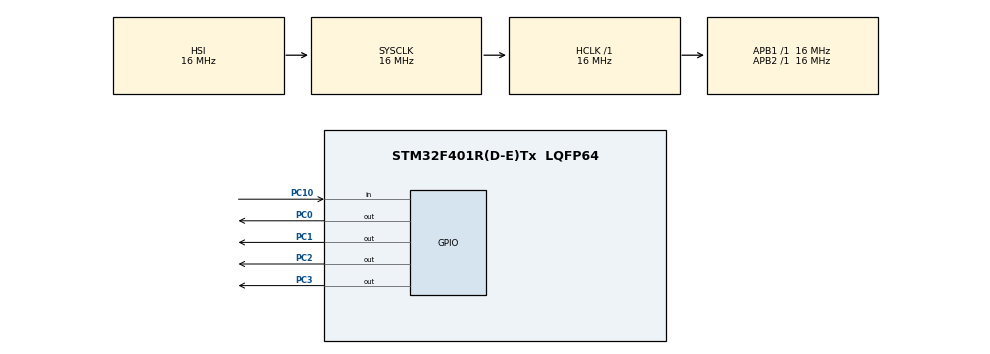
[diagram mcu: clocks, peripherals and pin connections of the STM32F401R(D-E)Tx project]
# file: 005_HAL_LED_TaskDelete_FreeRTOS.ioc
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FREERTOS.Tasks01=Task1,2,128,Task1Handler,Default,NULL,Dynamic,NULL,NULL;Task2,0,128,Task2Handler,Default,NULL,Dynamic,NULL,NULL
Mcu.Family=STM32F4
Mcu.Name=STM32F401R(D-E)Tx
Mcu.Package=LQFP64
NVIC.PriorityGroup=NVIC_PRIORITYGROUP_4
PC0.GPIO_Speed=GPIO_SPEED_FREQ_VERY_HIGH
PC0.Signal=GPIO_Output
PC1.GPIO_Speed=GPIO_SPEED_FREQ_VERY_HIGH
PC1.Signal=GPIO_Output
PC10.GPIO_PuPd=GPIO_PULLDOWN
PC10.Signal=GPIO_Input
PC2.GPIO_Speed=GPIO_SPEED_FREQ_VERY_HIGH
PC2.Signal=GPIO_Output
PC3.GPIO_Speed=GPIO_SPEED_FREQ_VERY_HIGH
PC3.Signal=GPIO_Output
ProjectManager.HeapSize=0x200
ProjectManager.StackSize=0x400
ProjectManager.TargetToolchain=STM32CubeIDE
RCC.AHBFreq_Value=16000000
RCC.APB1Freq_Value=16000000
RCC.APB2Freq_Value=16000000
RCC.CortexFreq_Value=16000000
RCC.HSE_VALUE=25000000
RCC.HSI_VALUE=16000000
RCC.LSE_VALUE=32768
RCC.SYSCLKFreq_VALUE=16000000
RCC.VCOOutputFreq_Value=192000000
VP_FREERTOS_VS_CMSIS_V1.Mode=CMSIS_V1
board=custom

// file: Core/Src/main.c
/* USER CODE BEGIN Header */
/**
  ******************************************************************************
  * @file           : main.c
  * @brief          : Main program body
  ******************************************************************************
  * @attention
  *
  * Copyright (c) 2023 STMicroelectronics.
  * All rights reserved.
  *
  * This software is licensed under terms that can be found in the LICENSE file
  * in the root directory of this software component.
  * If no LICENSE file comes with this software, it is provided AS-IS.
  *
  ******************************************************************************
  */
/* USER CODE END Header */
#include "main.h"
#include "cmsis_os.h"

osThreadId Task1Handle;
osThreadId Task2Handle;

void SystemClock_Config(void);
static void MX_GPIO_Init(void);
void Task1Handler(void const * argument);
void Task2Handler(void const * argument);

int main(void)
{

  /* MCU Configuration--------------------------------------------------------*/

  /* Reset of all peripherals, Initializes the Flash interface and the Systick. */
  HAL_Init();

  /* Configure the system clock */
  SystemClock_Config();

  /* Initialize all configured peripherals */
  MX_GPIO_Init();

  /* Create the thread(s) */
  /* definition and creation of Task1 */
  osThreadDef(Task1, Task1Handler, osPriorityHigh, 0, 128);
  Task1Handle = osThreadCreate(osThread(Task1), NULL);

  /* definition and creation of Task2 */
  osThreadDef(Task2, Task2Handler, osPriorityNormal, 0, 128);
  Task2Handle = osThreadCreate(osThread(Task2), NULL);

  /* Start scheduler */
  osKernelStart();
  /* We should never get here as control is now taken by the scheduler */
  /* Infinite loop */
  while (1)
  {

  }
}

void SystemClock_Config(void)
{
  RCC_OscInitTypeDef RCC_OscInitStruct = {0};
  RCC_ClkInitTypeDef RCC_ClkInitStruct = {0};

  /** Configure the main internal regulator output voltage
  */
  __HAL_RCC_PWR_CLK_ENABLE();
  __HAL_PWR_VOLTAGESCALING_CONFIG(PWR_REGULATOR_VOLTAGE_SCALE2);

  /** Initializes the RCC Oscillators according to the specified parameters
  * in the RCC_OscInitTypeDef structure.
  */
  RCC_OscInitStruct.OscillatorType = RCC_OSCILLATORTYPE_HSI;
  RCC_OscInitStruct.HSIState = RCC_HSI_ON;
  RCC_OscInitStruct.HSICalibrationValue = RCC_HSICALIBRATION_DEFAULT;
  RCC_OscInitStruct.PLL.PLLState = RCC_PLL_NONE;
  if (HAL_RCC_OscConfig(&RCC_OscInitStruct) != HAL_OK)
  {
    Error_Handler();
  }

  /** Initializes the CPU, AHB and APB buses clocks
  */
  RCC_ClkInitStruct.ClockType = RCC_CLOCKTYPE_HCLK|RCC_CLOCKTYPE_SYSCLK
                              |RCC_CLOCKTYPE_PCLK1|RCC_CLOCKTYPE_PCLK2;
  RCC_ClkInitStruct.SYSCLKSource = RCC_SYSCLKSOURCE_HSI;
  RCC_ClkInitStruct.AHBCLKDivider = RCC_SYSCLK_DIV1;
  RCC_ClkInitStruct.APB1CLKDivider = RCC_HCLK_DIV1;
  RCC_ClkInitStruct.APB2CLKDivider = RCC_HCLK_DIV1;

  if (HAL_RCC_ClockConfig(&RCC_ClkInitStruct, FLASH_LATENCY_0) != HAL_OK)
  {
    Error_Handler();
  }
}

static void MX_GPIO_Init(void)
{
  GPIO_InitTypeDef GPIO_InitStruct = {0};

  /* GPIO Ports Clock Enable */
  __HAL_RCC_GPIOC_CLK_ENABLE();

  /*Configure GPIO pin Output Level */
  HAL_GPIO_WritePin(GPIOC, GPIO_PIN_0|GPIO_PIN_1|GPIO_PIN_2|GPIO_PIN_3, GPIO_PIN_RESET);

  /*Configure GPIO pins : PC0 PC1 PC2 PC3 */
  GPIO_InitStruct.Pin = GPIO_PIN_0|GPIO_PIN_1|GPIO_PIN_2|GPIO_PIN_3;
  GPIO_InitStruct.Mode = GPIO_MODE_OUTPUT_PP;
  GPIO_InitStruct.Pull = GPIO_NOPULL;
  GPIO_InitStruct.Speed = GPIO_SPEED_FREQ_VERY_HIGH;
  HAL_GPIO_Init(GPIOC, &GPIO_InitStruct);

  /*Configure GPIO pin : PC10 */
  GPIO_InitStruct.Pin = GPIO_PIN_10;
  GPIO_InitStruct.Mode = GPIO_MODE_INPUT;
  GPIO_InitStruct.Pull = GPIO_PULLDOWN;
  HAL_GPIO_Init(GPIOC, &GPIO_InitStruct);

}

void Task1Handler(void const * argument)
{
  /* USER CODE BEGIN 5 */
  /* Infinite loop */
  for(;;)
  {
	  HAL_GPIO_TogglePin(GPIOC, GPIO_PIN_0|GPIO_PIN_1);
	  HAL_Delay(100);
	  if(HAL_GPIO_ReadPin(GPIOC,GPIO_PIN_10) == GPIO_PIN_SET)
	  {
		  HAL_GPIO_WritePin(GPIOC, GPIO_PIN_0|GPIO_PIN_1,GPIO_PIN_RESET);
		  osThreadTerminate(Task1Handle);
	  }
  }
  /* USER CODE END 5 */
}

void Task2Handler(void const * argument)
{
  /* USER CODE BEGIN Task2Handler */
  /* Infinite loop */
  for(;;)
  {
	  HAL_GPIO_TogglePin(GPIOC, GPIO_PIN_2|GPIO_PIN_3);
	  HAL_Delay(100);

  }
  /* USER CODE END Task2Handler */
}

void Error_Handler(void)
{
  __disable_irq();
  while (1)
  {
  }
}
